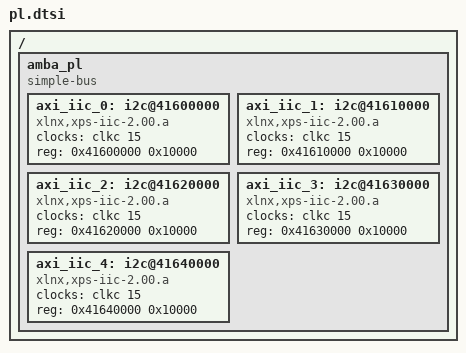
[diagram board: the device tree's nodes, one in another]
/*
 * CAUTION: This file is automatically generated by Xilinx.
 * Version:
 * Today is: Tue Nov 08 15:52:41 2016
*/


/ {
	amba_pl: amba_pl {
		#address-cells = <1>;
		#size-cells = <1>;
		compatible = "simple-bus";
		ranges ;
		axi_iic_0: i2c@41600000 {
			#address-cells = <1>;
			#size-cells = <0>;
			clock-names = "ref_clk";
			clocks = <&clkc 15>;
			compatible = "xlnx,xps-iic-2.00.a";
			reg = <0x41600000 0x10000>;
		};
		axi_iic_1: i2c@41610000 {
			#address-cells = <1>;
			#size-cells = <0>;
			clock-names = "ref_clk";
			clocks = <&clkc 15>;
			compatible = "xlnx,xps-iic-2.00.a";
			reg = <0x41610000 0x10000>;
		};
		axi_iic_2: i2c@41620000 {
			#address-cells = <1>;
			#size-cells = <0>;
			clock-names = "ref_clk";
			clocks = <&clkc 15>;
			compatible = "xlnx,xps-iic-2.00.a";
			reg = <0x41620000 0x10000>;
		};
		axi_iic_3: i2c@41630000 {
			#address-cells = <1>;
			#size-cells = <0>;
			clock-names = "ref_clk";
			clocks = <&clkc 15>;
			compatible = "xlnx,xps-iic-2.00.a";
			reg = <0x41630000 0x10000>;
		};
		axi_iic_4: i2c@41640000 {
			#address-cells = <1>;
			#size-cells = <0>;
			clock-names = "ref_clk";
			clocks = <&clkc 15>;
			compatible = "xlnx,xps-iic-2.00.a";
			reg = <0x41640000 0x10000>;
		};
	};
};
